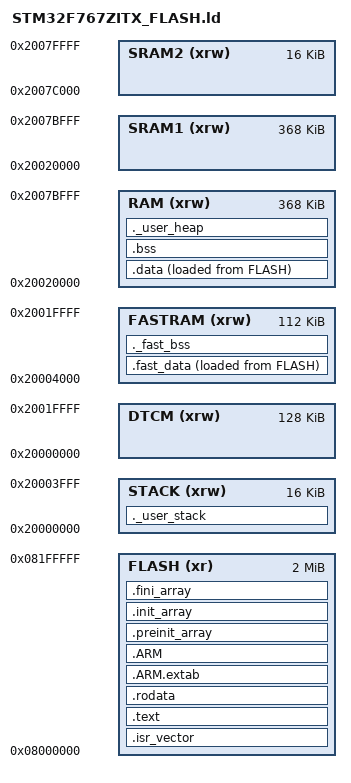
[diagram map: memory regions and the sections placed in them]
/*
******************************************************************************
**
** @file        : LinkerScript.ld
**
** @author      : Auto-generated by STM32CubeIDE
**
**  Abstract    : Linker script for NUCLEO-F767ZI Board embedding STM32F767ZITx Device from stm32f7 series
**                      2048KBytes FLASH
**                      512KBytes RAM
**
**                Set heap size, stack size and stack location according
**                to application requirements.
**
**                Set memory bank area and size if external memory is used
**
**  Target      : STMicroelectronics STM32
**
**  Distribution: The file is distributed as is, without any warranty
**                of any kind.
**
******************************************************************************
** @attention
**
** Copyright (c) 2024 STMicroelectronics.
** All rights reserved.
**
** This software is licensed under terms that can be found in the LICENSE file
** in the root directory of this software component.
** If no LICENSE file comes with this software, it is provided AS-IS.
**
******************************************************************************
*/

/*
I am splitting things into multiple memory regions.

DTCM: Very fast memory: Use for stack and specific variables.

SRAM1: Regular RAM: Use for most stuff by default.

SRAM2: Slower RAM than SRAM1: Use only for things that need
       DMA not to conflict with SRAM1.
       
I created a special end of heap symbol, and implemented my own
_sbrk using it. That symbol is _heap_end. We no longer place the
stack to be growing down toward the heap.

So, memory usage:

DTCM
  Variables
  <empty>
  Stack starts at end
SRAM1
  .data
  .bss
SRAM2
  Nothing for now
*/

/* Entry Point */
ENTRY(Reset_Handler)

/* Highest address of the user mode stack */
_estack = ORIGIN(DTCM) + LENGTH(DTCM); /* end of fast "DTCM" type memory */

_Min_Heap_Size = 0x200; /* required amount of heap */
_Min_Stack_Size = 0x400; /* required amount of stack */
_DTCM_Stack_Size = 0x4000; /* 16 KB */

/* Heap End */
_heap_end = ORIGIN(RAM) + LENGTH(RAM);

/* RAM details:
   RM0410 Rev 5 p77
   DTCM: 0x2000 0000 - 0x2001 FFFF (128KB) Data Tightly Coupled Memory
   SRAM1 0x2002 0000 - 0x2007 BFFF (368KB)
   SRAM2 0x2007 C000 - 0x2007 FFFF ( 16KB)
   ITCM: 0x0000 0000 - 0x0000 3FFF ( 16KB)

   Let's see if it runs faster if I define all RAM to use the DTCM
   
  RAM    (xrw)    : ORIGIN = 0x20000000,   LENGTH = 128K
    LPT: 85 (all memory in DTCM)
  RAM    (xrw)    : ORIGIN = 0x20000000,   LENGTH = 512K
    LPT: 79 (stack not in DTCM)
    
  Later, I split it up so Stack is all in DTCM and it runs faster.
  Then, I made the Stack & "fast BSS" and "fast RAM" to contain the
  I/O queues, and now it runs at 85 too.
   
*/

/*

The Mamory map below 0x2000 0000 is Reserved 0x1FFF 0020 - 0x1FFF FFFF.
I wonder if it's fine to let the stack over-grow down to there?

We'll make the stack grow down AWAY from anything it can overwrite.
*/

/* Memories definition */
MEMORY
{
  RAM    (xrw)    : ORIGIN = 0x20020000,   LENGTH = 368K /* SRAM1 */
  STACK  (xrw)    : ORIGIN = 0x20000000,   LENGTH = _DTCM_Stack_Size /* DTCM bottom */
  FASTRAM (xrw)   : ORIGIN = 0x20000000 + _DTCM_Stack_Size, LENGTH = 128K - _DTCM_Stack_Size /* DTCM TOP */
  
  /* Three actual SRAMs */
  DTCM   (xrw)    : ORIGIN = 0x20000000    LENGTH = 128K
  SRAM1  (xrw)    : ORIGIN = 0x20020000,   LENGTH = 368K
  SRAM2  (xrw)    : ORIGIN = 0x2007C000,   LENGTH = 16k
  
  FLASH  (xr )    : ORIGIN = 0x08000000,   LENGTH = 2048K
}

/* Sections */
SECTIONS
{
  /* The startup code into "FLASH" Rom type memory */
  .isr_vector :
  {
    . = ALIGN(4);
    KEEP(*(.isr_vector)) /* Startup code */
    . = ALIGN(4);
  } >FLASH

  /* The program code and other data into "FLASH" Rom type memory */
  .text :
  {
    . = ALIGN(4);
    *(.text)           /* .text sections (code) */
    *(.text*)          /* .text* sections (code) */
    *(.glue_7)         /* glue arm to thumb code */
    *(.glue_7t)        /* glue thumb to arm code */
    *(.eh_frame)

    KEEP (*(.init))
    KEEP (*(.fini))

    . = ALIGN(4);
    _etext = .;        /* define a global symbols at end of code */
  } >FLASH

  /* Constant data into "FLASH" Rom type memory */
  .rodata :
  {
    . = ALIGN(4);
    *(.rodata)         /* .rodata sections (constants, strings, etc.) */
    *(.rodata*)        /* .rodata* sections (constants, strings, etc.) */
    . = ALIGN(4);
  } >FLASH

  .ARM.extab (READONLY) : /* The "READONLY" keyword is only supported in GCC11 and later, remove it if using GCC10 or earlier. */
  {
    . = ALIGN(4);
    *(.ARM.extab* .gnu.linkonce.armextab.*)
    . = ALIGN(4);
  } >FLASH

  .ARM (READONLY) : /* The "READONLY" keyword is only supported in GCC11 and later, remove it if using GCC10 or earlier. */
  {
    . = ALIGN(4);
    __exidx_start = .;
    *(.ARM.exidx*)
    __exidx_end = .;
    . = ALIGN(4);
  } >FLASH

  .preinit_array (READONLY) : /* The "READONLY" keyword is only supported in GCC11 and later, remove it if using GCC10 or earlier. */
  {
    . = ALIGN(4);
    PROVIDE_HIDDEN (__preinit_array_start = .);
    KEEP (*(.preinit_array*))
    PROVIDE_HIDDEN (__preinit_array_end = .);
    . = ALIGN(4);
  } >FLASH

  .init_array (READONLY) : /* The "READONLY" keyword is only supported in GCC11 and later, remove it if using GCC10 or earlier. */
  {
    . = ALIGN(4);
    PROVIDE_HIDDEN (__init_array_start = .);
    KEEP (*(SORT(.init_array.*)))
    KEEP (*(.init_array*))
    PROVIDE_HIDDEN (__init_array_end = .);
    . = ALIGN(4);
  } >FLASH

  .fini_array (READONLY) : /* The "READONLY" keyword is only supported in GCC11 and later, remove it if using GCC10 or earlier. */
  {
    . = ALIGN(4);
    PROVIDE_HIDDEN (__fini_array_start = .);
    KEEP (*(SORT(.fini_array.*)))
    KEEP (*(.fini_array*))
    PROVIDE_HIDDEN (__fini_array_end = .);
    . = ALIGN(4);
  } >FLASH

  /* Used by the startup to initialize data & fast_data */
  _sidata = LOADADDR(.data);
  _sifastdata = LOADADDR(.fast_data);

  /* Initialized data sections into "RAM" Ram type memory */
  .data :
  {
    . = ALIGN(4);
    _sdata = .;        /* create a global symbol at data start */
    *(.data)           /* .data sections */
    *(.data*)          /* .data* sections */
    *(.RamFunc)        /* .RamFunc sections */
    *(.RamFunc*)       /* .RamFunc* sections */

    . = ALIGN(4);
    _edata = .;        /* define a global symbol at data end */

  } >RAM AT> FLASH

  /* Uninitialized data section into "RAM" Ram type memory */
  . = ALIGN(4);
  .bss :
  {
    /* This is used by the startup in order to initialize the .bss section */
    _sbss = .;         /* define a global symbol at bss start */
    __bss_start__ = _sbss;
    *(.bss)
    *(.bss*)
    *(COMMON)

    . = ALIGN(4);
    _ebss = .;         /* define a global symbol at bss end */
    __bss_end__ = _ebss;
  } >RAM

  /* User_heap section, used to check that there is enough "RAM" Ram  type memory left */
  ._user_heap :
  {
    . = ALIGN(8);
    PROVIDE ( end = . );
    PROVIDE ( _end = . );
    . = . + _Min_Heap_Size;
    . = ALIGN(8);
  } >RAM

  /* *************************************************** */
  
  /* Initialized data sections into "RAM" Ram type memory */
  .fast_data :
  {
    . = ALIGN(4);
    _sfastdata = .;        /* create a global symbol at data start */
    *(.fast_data)          /* .fast_data sections */
    *(.fast_data*)         /* .fast_data* sections */
    . = ALIGN(4);
    _efastdata = .;        /* define a global symbol at data end */

  } >FASTRAM AT> FLASH

  /* Fast data section */
  ._fast_bss :
  {
    _sfbss = .;
    . = ALIGN(4);
    *(.fast_bss)
    *(.fast_bss*)
    . = ALIGN(4);
    _efbss = .;
  } >FASTRAM
  
  /* Fast noinit section - not used */
  /*
  ._fast_noinit (NOLOAD) :
  {
    _sfnoinit = .;
    . = ALIGN(4);
    KEEP(*(*.noinit*))
    . = ALIGN(4);
    _efnoinit = .;
  } >FASTRAM
  */
  
  
  
  ._user_stack :
  {
    . = ALIGN(8);
    . = . + _Min_Stack_Size;
    . = ALIGN(8);
  } >STACK
  
  /* Stack (grows toward fast data section) */

  /* Remove information from the compiler libraries */
  /DISCARD/ :
  {
    libc.a ( * )
    libm.a ( * )
    libgcc.a ( * )
  }

  .ARM.attributes 0 : { *(.ARM.attributes) }
}
